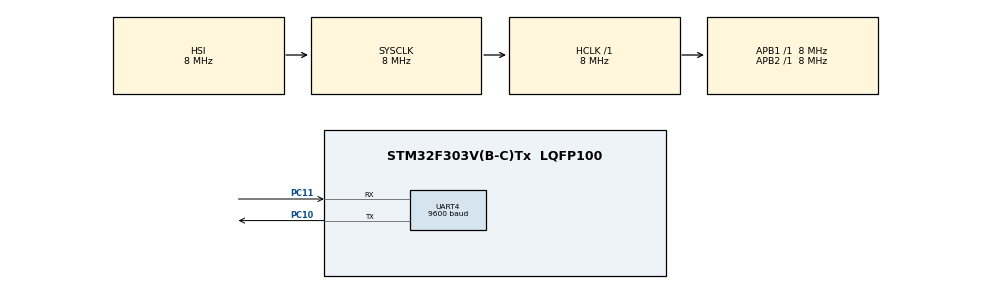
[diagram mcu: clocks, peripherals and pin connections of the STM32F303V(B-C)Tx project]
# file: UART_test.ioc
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Mcu.Family=STM32F3
Mcu.Name=STM32F303V(B-C)Tx
Mcu.Package=LQFP100
NVIC.PriorityGroup=NVIC_PRIORITYGROUP_4
NVIC.UART4_IRQn=true\:0\:0\:false\:false\:true\:true\:true
PC10.Mode=Asynchronous
PC10.Signal=UART4_TX
PC11.Mode=Asynchronous
PC11.Signal=UART4_RX
ProjectManager.HeapSize=0x200
ProjectManager.StackSize=0x400
ProjectManager.TargetToolchain=EWARM V8.32
RCC.AHBFreq_Value=8000000
RCC.APB1Freq_Value=8000000
RCC.APB2Freq_Value=8000000
RCC.CortexFreq_Value=8000000
RCC.HSE_VALUE=8000000
RCC.HSI_VALUE=8000000
RCC.LSE_VALUE=32768
RCC.SYSCLKFreq_VALUE=8000000
UART4.BaudRate=9600
board=custom

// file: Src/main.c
/* USER CODE BEGIN Header */
/**
  ******************************************************************************
  * @file           : main.c
  * @brief          : Main program body
  ******************************************************************************
  * @attention
  *
  * <h2><center>&copy; Copyright (c) 2020 STMicroelectronics.
  * All rights reserved.</center></h2>
  *
  * This software component is licensed by ST under BSD 3-Clause license,
  * the "License"; You may not use this file except in compliance with the
  * License. You may obtain a copy of the License at:
  *                        opensource.org/licenses/BSD-3-Clause
  *
  ******************************************************************************
  */
/* USER CODE END Header */

#include "main.h"

UART_HandleTypeDef huart4;

void SystemClock_Config(void);
static void MX_GPIO_Init(void);
static void MX_UART4_Init(void);

int main(void)
{

  /* MCU Configuration--------------------------------------------------------*/

  /* Reset of all peripherals, Initializes the Flash interface and the Systick. */
  HAL_Init();

  /* Configure the system clock */
  SystemClock_Config();

  /* Initialize all configured peripherals */
  MX_GPIO_Init();
  MX_UART4_Init();

  /* Infinite loop */
  /* USER CODE BEGIN WHILE */
  uint8_t buff[2] = {0,};
  while (1)
  {
    HAL_UART_Receive_IT(&huart4, (uint8_t*)buff, 2);
    if (buff[0] == '1'){
        HAL_UART_Transmit_IT(&huart4, (uint8_t*)"Number_1\r\n", 10);
        buff[0] = 3;
    }
    if (buff[0] == '0'){
        HAL_UART_Transmit_IT(&huart4, (uint8_t*)"Number_0\r\n", 10);
        buff[0] = 3;
    }
    else
        HAL_UART_Transmit_IT(&huart4, (uint8_t*)"Nothing\r\n", 9);
    HAL_Delay(1000);
    /* USER CODE END WHILE */

  }
}

void SystemClock_Config(void)
{
  RCC_OscInitTypeDef RCC_OscInitStruct = {0};
  RCC_ClkInitTypeDef RCC_ClkInitStruct = {0};
  RCC_PeriphCLKInitTypeDef PeriphClkInit = {0};

  /** Initializes the CPU, AHB and APB busses clocks
  */
  RCC_OscInitStruct.OscillatorType = RCC_OSCILLATORTYPE_HSI;
  RCC_OscInitStruct.HSIState = RCC_HSI_ON;
  RCC_OscInitStruct.HSICalibrationValue = RCC_HSICALIBRATION_DEFAULT;
  RCC_OscInitStruct.PLL.PLLState = RCC_PLL_NONE;
  if (HAL_RCC_OscConfig(&RCC_OscInitStruct) != HAL_OK)
  {
    Error_Handler();
  }
  /** Initializes the CPU, AHB and APB busses clocks
  */
  RCC_ClkInitStruct.ClockType = RCC_CLOCKTYPE_HCLK|RCC_CLOCKTYPE_SYSCLK
                              |RCC_CLOCKTYPE_PCLK1|RCC_CLOCKTYPE_PCLK2;
  RCC_ClkInitStruct.SYSCLKSource = RCC_SYSCLKSOURCE_HSI;
  RCC_ClkInitStruct.AHBCLKDivider = RCC_SYSCLK_DIV1;
  RCC_ClkInitStruct.APB1CLKDivider = RCC_HCLK_DIV1;
  RCC_ClkInitStruct.APB2CLKDivider = RCC_HCLK_DIV1;

  if (HAL_RCC_ClockConfig(&RCC_ClkInitStruct, FLASH_LATENCY_0) != HAL_OK)
  {
    Error_Handler();
  }
  PeriphClkInit.PeriphClockSelection = RCC_PERIPHCLK_UART4;
  PeriphClkInit.Uart4ClockSelection = RCC_UART4CLKSOURCE_PCLK1;
  if (HAL_RCCEx_PeriphCLKConfig(&PeriphClkInit) != HAL_OK)
  {
    Error_Handler();
  }
}

static void MX_UART4_Init(void)
{

  huart4.Instance = UART4;
  huart4.Init.BaudRate = 9600;
  huart4.Init.WordLength = UART_WORDLENGTH_8B;
  huart4.Init.StopBits = UART_STOPBITS_1;
  huart4.Init.Parity = UART_PARITY_NONE;
  huart4.Init.Mode = UART_MODE_TX_RX;
  huart4.Init.HwFlowCtl = UART_HWCONTROL_NONE;
  huart4.Init.OverSampling = UART_OVERSAMPLING_16;
  huart4.Init.OneBitSampling = UART_ONE_BIT_SAMPLE_DISABLE;
  huart4.AdvancedInit.AdvFeatureInit = UART_ADVFEATURE_NO_INIT;
  if (HAL_UART_Init(&huart4) != HAL_OK)
  {
    Error_Handler();
  }

}

static void MX_GPIO_Init(void)
{

  /* GPIO Ports Clock Enable */
  __HAL_RCC_GPIOC_CLK_ENABLE();

}

void Error_Handler(void)
{
}

/************************ (C) COPYRIGHT STMicroelectronics *****END OF FILE****/
